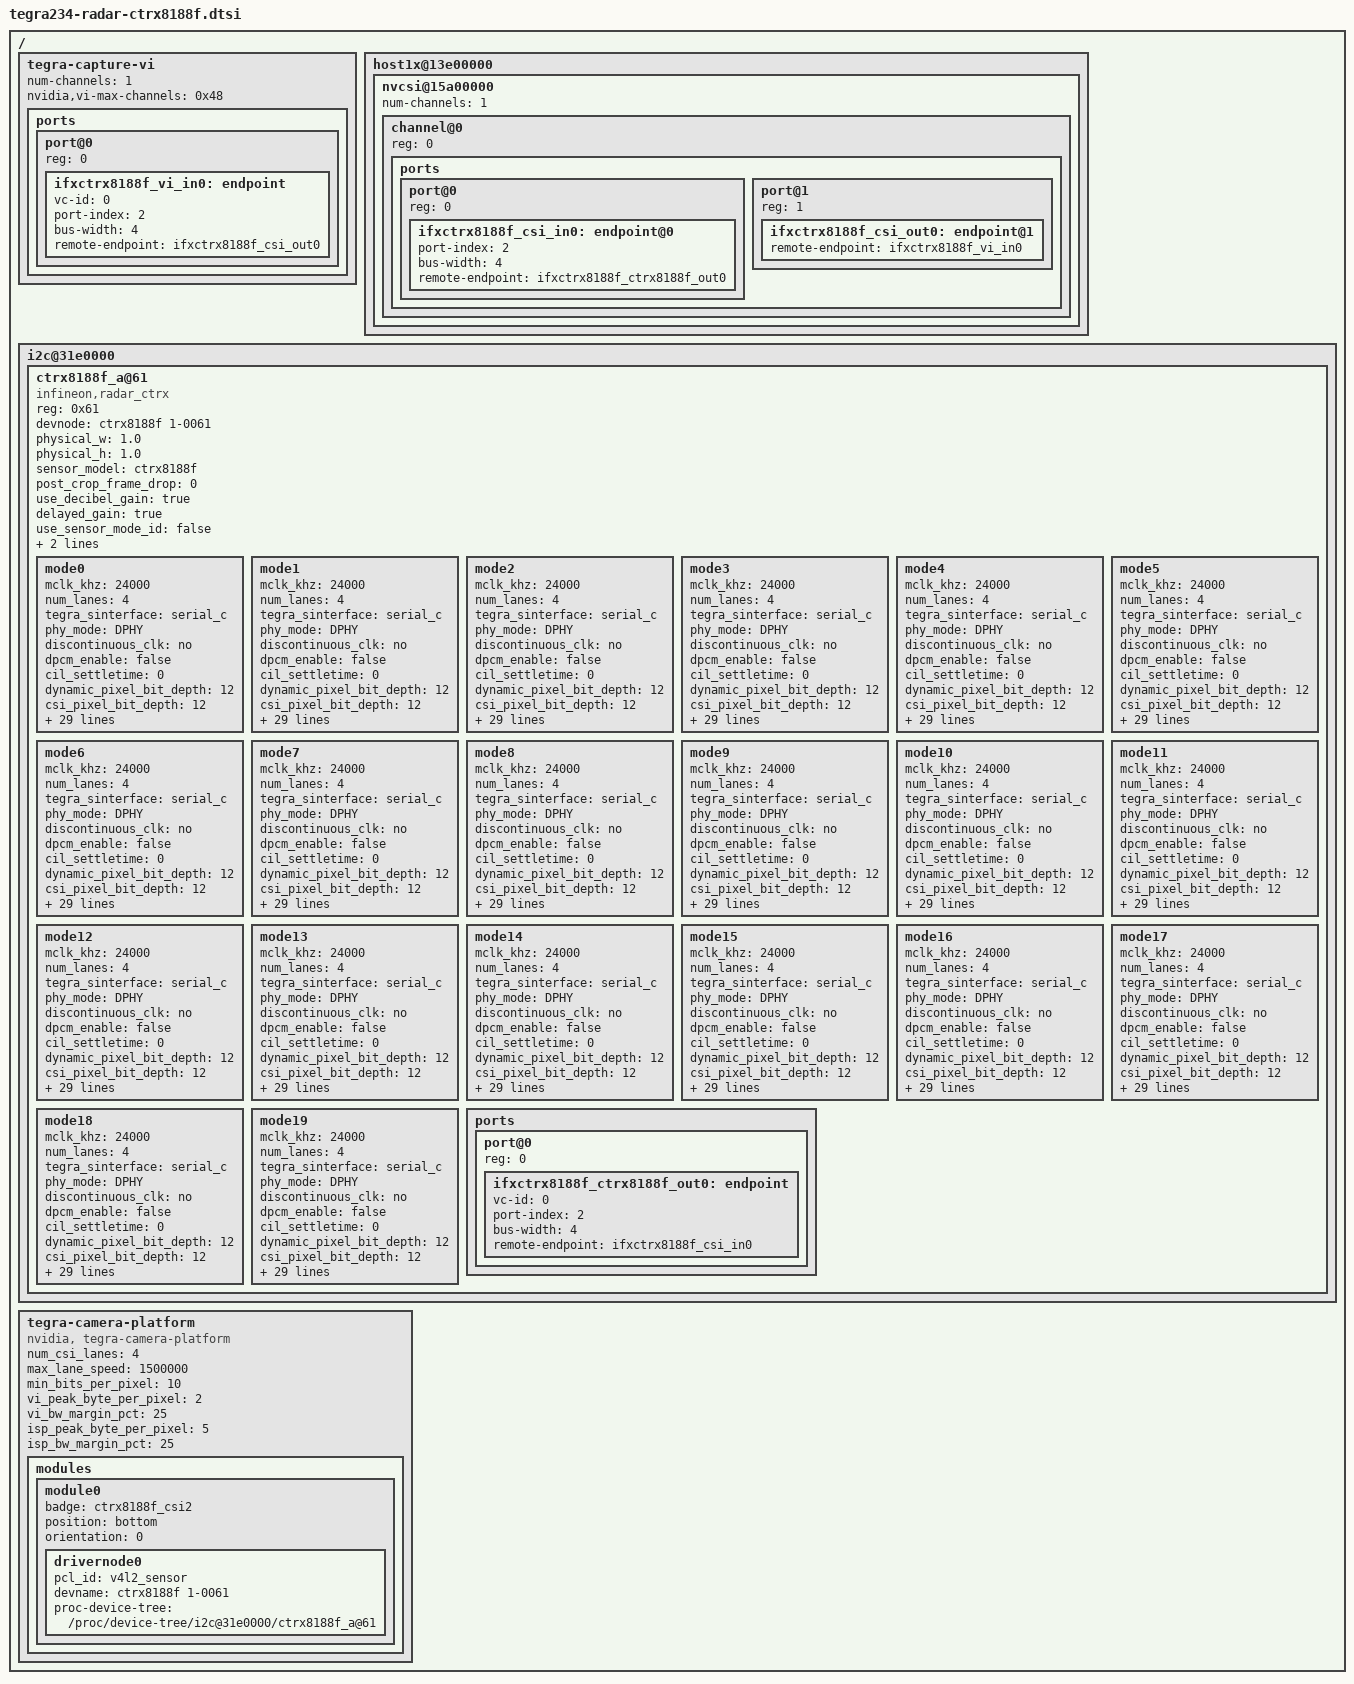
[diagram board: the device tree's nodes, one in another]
/*
 * Copyright (c) 2016-2021, NVIDIA CORPORATION.  All rights reserved.
 *
 * This program is free software; you can redistribute it and/or modify it
 * under the terms and conditions of the GNU General Public License,
 * version 2, as published by the Free Software Foundation.
 *
 * This program is distributed in the hope it will be useful, but WITHOUT
 * ANY WARRANTY; without even the implied warranty of MERCHANTABILITY or
 * FITNESS FOR A PARTICULAR PURPOSE.  See the GNU General Public License for
 * more details.
 *
 * You should have received a copy of the GNU General Public License
 * along with this program.  If not, see <http://www.gnu.org/licenses/>.
 */

/ {
	tegra-capture-vi {
		num-channels = <1>;
		nvidia,vi-max-channels = <0x48>;
		ports {
			#address-cells = <1>;
			#size-cells = <0>;
			port@0 {
				reg = <0>;
				status = "okay";
				ifxctrx8188f_vi_in0: endpoint {
					vc-id = <0>;
					port-index = <2>;
					bus-width = <4>;
					status = "okay";
					remote-endpoint = <&ifxctrx8188f_csi_out0>;
				};
			};
		};
	};

	host1x@13e00000 {
		nvcsi@15a00000 {
			num-channels = <1>;
			#address-cells = <1>;
			#size-cells = <0>;
			channel@0 {
				reg = <0>;
				status = "okay";
				ports {
					#address-cells = <1>;
					#size-cells = <0>;
					port@0 {
						reg = <0>;
						status = "okay";
						ifxctrx8188f_csi_in0: endpoint@0 {
							port-index = <2>;
							bus-width = <4>;
							status = "okay";
							remote-endpoint = <&ifxctrx8188f_ctrx8188f_out0>;
						};
					};
					port@1 {
						reg = <1>;
						status = "okay";
						ifxctrx8188f_csi_out0: endpoint@1 {
							status = "okay";
							remote-endpoint = <&ifxctrx8188f_vi_in0>;
						};
					};
				};
			};
		};
	};

	i2c@31e0000 {
    ctrx8188f_a@61 {
			compatible = "infineon,radar_ctrx";
			reg = <0x61>;
			devnode = "ctrx8188f 1-0061";
			physical_w = "1.0";
			physical_h = "1.0";
			sensor_model = "ctrx8188f";
			post_crop_frame_drop = "0";
			use_decibel_gain = "true";
			delayed_gain = "true";
			use_sensor_mode_id = "false";
			status = "okay";
			clocks = <0x02 0x24 0x02 0x24>;
			clock-names = "extperiph1", "pllp_grtba";
			mclk = "extperiph1";

			mode0 {
				mclk_khz = "24000";
				num_lanes = "4";
				tegra_sinterface = "serial_c";
				phy_mode = "DPHY";
				discontinuous_clk = "no";
				dpcm_enable = "false";
				cil_settletime = "0";
				dynamic_pixel_bit_depth = "12";
				csi_pixel_bit_depth = "12";
				mode_type = "bayer";
				pixel_phase = "rggb";
				vc_id = "0";
				active_w = "1024";
				active_h = "256";
				readout_orientation = "0";
				line_length = "1024";
				inherent_gain = "1";
				mclk_multiplier = "14.58";
				pix_clk_hz = "400000000";
				serdes_pix_clk_hz = "400000000";
				gain_factor = "10";
				min_gain_val = "10";
				max_gain_val = "110";
				step_gain_val = "1";
				default_gain = "10";
				min_hdr_ratio = "1";
				max_hdr_ratio = "1";
				framerate_factor = "1000000";
				min_framerate = "30000000";
				max_framerate = "30000000";
				step_framerate = "1";
				default_framerate = "30000000";
				exposure_factor = "1000000";
				min_exp_time = "30";
				max_exp_time = "33000";
				step_exp_time = "1";
				default_exp_time = "30000";
				embedded_metadata_height = "0";
			};

			mode1 {
			mclk_khz = "24000";
			num_lanes = "4";
			tegra_sinterface = "serial_c";
			phy_mode = "DPHY";
			discontinuous_clk = "no";
			dpcm_enable = "false";
			cil_settletime = "0";
			dynamic_pixel_bit_depth = "12";
			csi_pixel_bit_depth = "12";
			mode_type = "bayer";
			pixel_phase = "rggb";
			vc_id = "0";
			active_w = "2048";
			active_h = "256";
			readout_orientation = "0";
			line_length = "2048";
			inherent_gain = "1";
			mclk_multiplier = "14.58";
			pix_clk_hz = "400000000";
			serdes_pix_clk_hz = "400000000";
			gain_factor = "10";
			min_gain_val = "10";
			max_gain_val = "110";
			step_gain_val = "1";
			default_gain = "10";
			min_hdr_ratio = "1";
			max_hdr_ratio = "1";
			framerate_factor = "1000000";
			min_framerate = "30000000";
			max_framerate = "30000000";
			step_framerate = "1";
			default_framerate = "30000000";
			exposure_factor = "1000000";
			min_exp_time = "30";
			max_exp_time = "33000";
			step_exp_time = "1";
			default_exp_time = "30000";
			embedded_metadata_height = "0";
			};

			mode2 {
			mclk_khz = "24000";
			num_lanes = "4";
			tegra_sinterface = "serial_c";
			phy_mode = "DPHY";
			discontinuous_clk = "no";
			dpcm_enable = "false";
			cil_settletime = "0";
			dynamic_pixel_bit_depth = "12";
			csi_pixel_bit_depth = "12";
			mode_type = "bayer";
			pixel_phase = "rggb";
			vc_id = "0";
			active_w = "4096";
			active_h = "256";
			readout_orientation = "0";
			line_length = "4096";
			inherent_gain = "1";
			mclk_multiplier = "14.58";
			pix_clk_hz = "400000000";
			serdes_pix_clk_hz = "400000000";
			gain_factor = "10";
			min_gain_val = "10";
			max_gain_val = "110";
			step_gain_val = "1";
			default_gain = "10";
			min_hdr_ratio = "1";
			max_hdr_ratio = "1";
			framerate_factor = "1000000";
			min_framerate = "30000000";
			max_framerate = "30000000";
			step_framerate = "1";
			default_framerate = "30000000";
			exposure_factor = "1000000";
			min_exp_time = "30";
			max_exp_time = "33000";
			step_exp_time = "1";
			default_exp_time = "30000";
			embedded_metadata_height = "0";
			};

			mode3 {
			mclk_khz = "24000";
			num_lanes = "4";
			tegra_sinterface = "serial_c";
			phy_mode = "DPHY";
			discontinuous_clk = "no";
			dpcm_enable = "false";
			cil_settletime = "0";
			dynamic_pixel_bit_depth = "12";
			csi_pixel_bit_depth = "12";
			mode_type = "bayer";
			pixel_phase = "rggb";
			vc_id = "0";
			active_w = "8192";
			active_h = "256";
			readout_orientation = "0";
			line_length = "8192";
			inherent_gain = "1";
			mclk_multiplier = "14.58";
			pix_clk_hz = "400000000";
			serdes_pix_clk_hz = "400000000";
			gain_factor = "10";
			min_gain_val = "10";
			max_gain_val = "110";
			step_gain_val = "1";
			default_gain = "10";
			min_hdr_ratio = "1";
			max_hdr_ratio = "1";
			framerate_factor = "1000000";
			min_framerate = "30000000";
			max_framerate = "30000000";
			step_framerate = "1";
			default_framerate = "30000000";
			exposure_factor = "1000000";
			min_exp_time = "30";
			max_exp_time = "33000";
			step_exp_time = "1";
			default_exp_time = "30000";
			embedded_metadata_height = "0";
			};

			mode4 {
			mclk_khz = "24000";
			num_lanes = "4";
			tegra_sinterface = "serial_c";
			phy_mode = "DPHY";
			discontinuous_clk = "no";
			dpcm_enable = "false";
			cil_settletime = "0";
			dynamic_pixel_bit_depth = "12";
			csi_pixel_bit_depth = "12";
			mode_type = "bayer";
			pixel_phase = "rggb";
			vc_id = "0";
			active_w = "16384";
			active_h = "256";
			readout_orientation = "0";
			line_length = "16384";
			inherent_gain = "1";
			mclk_multiplier = "14.58";
			pix_clk_hz = "400000000";
			serdes_pix_clk_hz = "400000000";
			gain_factor = "10";
			min_gain_val = "10";
			max_gain_val = "110";
			step_gain_val = "1";
			default_gain = "10";
			min_hdr_ratio = "1";
			max_hdr_ratio = "1";
			framerate_factor = "1000000";
			min_framerate = "30000000";
			max_framerate = "30000000";
			step_framerate = "1";
			default_framerate = "30000000";
			exposure_factor = "1000000";
			min_exp_time = "30";
			max_exp_time = "33000";
			step_exp_time = "1";
			default_exp_time = "30000";
			embedded_metadata_height = "0";
			};

			mode5 {
			mclk_khz = "24000";
			num_lanes = "4";
			tegra_sinterface = "serial_c";
			phy_mode = "DPHY";
			discontinuous_clk = "no";
			dpcm_enable = "false";
			cil_settletime = "0";
			dynamic_pixel_bit_depth = "12";
			csi_pixel_bit_depth = "12";
			mode_type = "bayer";
			pixel_phase = "rggb";
			vc_id = "0";
			active_w = "1024";
			active_h = "512";
			readout_orientation = "0";
			line_length = "1024";
			inherent_gain = "1";
			mclk_multiplier = "14.58";
			pix_clk_hz = "400000000";
			serdes_pix_clk_hz = "400000000";
			gain_factor = "10";
			min_gain_val = "10";
			max_gain_val = "110";
			step_gain_val = "1";
			default_gain = "10";
			min_hdr_ratio = "1";
			max_hdr_ratio = "1";
			framerate_factor = "1000000";
			min_framerate = "30000000";
			max_framerate = "30000000";
			step_framerate = "1";
			default_framerate = "30000000";
			exposure_factor = "1000000";
			min_exp_time = "30";
			max_exp_time = "33000";
			step_exp_time = "1";
			default_exp_time = "30000";
			embedded_metadata_height = "0";
			};

			mode6 {
			mclk_khz = "24000";
			num_lanes = "4";
			tegra_sinterface = "serial_c";
			phy_mode = "DPHY";
			discontinuous_clk = "no";
			dpcm_enable = "false";
			cil_settletime = "0";
			dynamic_pixel_bit_depth = "12";
			csi_pixel_bit_depth = "12";
			mode_type = "bayer";
			pixel_phase = "rggb";
			vc_id = "0";
			active_w = "2048";
			active_h = "512";
			readout_orientation = "0";
			line_length = "2048";
			inherent_gain = "1";
			mclk_multiplier = "14.58";
			pix_clk_hz = "400000000";
			serdes_pix_clk_hz = "400000000";
			gain_factor = "10";
			min_gain_val = "10";
			max_gain_val = "110";
			step_gain_val = "1";
			default_gain = "10";
			min_hdr_ratio = "1";
			max_hdr_ratio = "1";
			framerate_factor = "1000000";
			min_framerate = "30000000";
			max_framerate = "30000000";
			step_framerate = "1";
			default_framerate = "30000000";
			exposure_factor = "1000000";
			min_exp_time = "30";
			max_exp_time = "33000";
			step_exp_time = "1";
			default_exp_time = "30000";
			embedded_metadata_height = "0";
			};

			mode7 {
			mclk_khz = "24000";
			num_lanes = "4";
			tegra_sinterface = "serial_c";
			phy_mode = "DPHY";
			discontinuous_clk = "no";
			dpcm_enable = "false";
			cil_settletime = "0";
			dynamic_pixel_bit_depth = "12";
			csi_pixel_bit_depth = "12";
			mode_type = "bayer";
			pixel_phase = "rggb";
			vc_id = "0";
			active_w = "4096";
			active_h = "512";
			readout_orientation = "0";
			line_length = "4096";
			inherent_gain = "1";
			mclk_multiplier = "14.58";
			pix_clk_hz = "400000000";
			serdes_pix_clk_hz = "400000000";
			gain_factor = "10";
			min_gain_val = "10";
			max_gain_val = "110";
			step_gain_val = "1";
			default_gain = "10";
			min_hdr_ratio = "1";
			max_hdr_ratio = "1";
			framerate_factor = "1000000";
			min_framerate = "30000000";
			max_framerate = "30000000";
			step_framerate = "1";
			default_framerate = "30000000";
			exposure_factor = "1000000";
			min_exp_time = "30";
			max_exp_time = "33000";
			step_exp_time = "1";
			default_exp_time = "30000";
			embedded_metadata_height = "0";
			};

			mode8 {
			mclk_khz = "24000";
			num_lanes = "4";
			tegra_sinterface = "serial_c";
			phy_mode = "DPHY";
			discontinuous_clk = "no";
			dpcm_enable = "false";
			cil_settletime = "0";
			dynamic_pixel_bit_depth = "12";
			csi_pixel_bit_depth = "12";
			mode_type = "bayer";
			pixel_phase = "rggb";
			vc_id = "0";
			active_w = "8192";
			active_h = "512";
			readout_orientation = "0";
			line_length = "8192";
			inherent_gain = "1";
			mclk_multiplier = "14.58";
			pix_clk_hz = "400000000";
			serdes_pix_clk_hz = "400000000";
			gain_factor = "10";
			min_gain_val = "10";
			max_gain_val = "110";
			step_gain_val = "1";
			default_gain = "10";
			min_hdr_ratio = "1";
			max_hdr_ratio = "1";
			framerate_factor = "1000000";
			min_framerate = "30000000";
			max_framerate = "30000000";
			step_framerate = "1";
			default_framerate = "30000000";
			exposure_factor = "1000000";
			min_exp_time = "30";
			max_exp_time = "33000";
			step_exp_time = "1";
			default_exp_time = "30000";
			embedded_metadata_height = "0";
			};

			mode9 {
			mclk_khz = "24000";
			num_lanes = "4";
			tegra_sinterface = "serial_c";
			phy_mode = "DPHY";
			discontinuous_clk = "no";
			dpcm_enable = "false";
			cil_settletime = "0";
			dynamic_pixel_bit_depth = "12";
			csi_pixel_bit_depth = "12";
			mode_type = "bayer";
			pixel_phase = "rggb";
			vc_id = "0";
			active_w = "16384";
			active_h = "512";
			readout_orientation = "0";
			line_length = "16384";
			inherent_gain = "1";
			mclk_multiplier = "14.58";
			pix_clk_hz = "400000000";
			serdes_pix_clk_hz = "400000000";
			gain_factor = "10";
			min_gain_val = "10";
			max_gain_val = "110";
			step_gain_val = "1";
			default_gain = "10";
			min_hdr_ratio = "1";
			max_hdr_ratio = "1";
			framerate_factor = "1000000";
			min_framerate = "30000000";
			max_framerate = "30000000";
			step_framerate = "1";
			default_framerate = "30000000";
			exposure_factor = "1000000";
			min_exp_time = "30";
			max_exp_time = "33000";
			step_exp_time = "1";
			default_exp_time = "30000";
			embedded_metadata_height = "0";
			};

			mode10 {
			mclk_khz = "24000";
			num_lanes = "4";
			tegra_sinterface = "serial_c";
			phy_mode = "DPHY";
			discontinuous_clk = "no";
			dpcm_enable = "false";
			cil_settletime = "0";
			dynamic_pixel_bit_depth = "12";
			csi_pixel_bit_depth = "12";
			mode_type = "bayer";
			pixel_phase = "rggb";
			vc_id = "0";
			active_w = "1024";
			active_h = "640";
			readout_orientation = "0";
			line_length = "1024";
			inherent_gain = "1";
			mclk_multiplier = "14.58";
			pix_clk_hz = "400000000";
			serdes_pix_clk_hz = "400000000";
			gain_factor = "10";
			min_gain_val = "10";
			max_gain_val = "110";
			step_gain_val = "1";
			default_gain = "10";
			min_hdr_ratio = "1";
			max_hdr_ratio = "1";
			framerate_factor = "1000000";
			min_framerate = "30000000";
			max_framerate = "30000000";
			step_framerate = "1";
			default_framerate = "30000000";
			exposure_factor = "1000000";
			min_exp_time = "30";
			max_exp_time = "33000";
			step_exp_time = "1";
			default_exp_time = "30000";
			embedded_metadata_height = "0";
			};

			mode11 {
			mclk_khz = "24000";
			num_lanes = "4";
			tegra_sinterface = "serial_c";
			phy_mode = "DPHY";
			discontinuous_clk = "no";
			dpcm_enable = "false";
			cil_settletime = "0";
			dynamic_pixel_bit_depth = "12";
			csi_pixel_bit_depth = "12";
			mode_type = "bayer";
			pixel_phase = "rggb";
			vc_id = "0";
			active_w = "2048";
			active_h = "640";
			readout_orientation = "0";
			line_length = "2048";
			inherent_gain = "1";
			mclk_multiplier = "14.58";
			pix_clk_hz = "400000000";
			serdes_pix_clk_hz = "400000000";
			gain_factor = "10";
			min_gain_val = "10";
			max_gain_val = "110";
			step_gain_val = "1";
			default_gain = "10";
			min_hdr_ratio = "1";
			max_hdr_ratio = "1";
			framerate_factor = "1000000";
			min_framerate = "30000000";
			max_framerate = "30000000";
			step_framerate = "1";
			default_framerate = "30000000";
			exposure_factor = "1000000";
			min_exp_time = "30";
			max_exp_time = "33000";
			step_exp_time = "1";
			default_exp_time = "30000";
			embedded_metadata_height = "0";
			};

			mode12 {
			mclk_khz = "24000";
			num_lanes = "4";
			tegra_sinterface = "serial_c";
			phy_mode = "DPHY";
			discontinuous_clk = "no";
			dpcm_enable = "false";
			cil_settletime = "0";
			dynamic_pixel_bit_depth = "12";
			csi_pixel_bit_depth = "12";
			mode_type = "bayer";
			pixel_phase = "rggb";
			vc_id = "0";
			active_w = "4096";
			active_h = "640";
			readout_orientation = "0";
			line_length = "4096";
			inherent_gain = "1";
			mclk_multiplier = "14.58";
			pix_clk_hz = "400000000";
			serdes_pix_clk_hz = "400000000";
			gain_factor = "10";
			min_gain_val = "10";
			max_gain_val = "110";
			step_gain_val = "1";
			default_gain = "10";
			min_hdr_ratio = "1";
			max_hdr_ratio = "1";
			framerate_factor = "1000000";
			min_framerate = "30000000";
			max_framerate = "30000000";
			step_framerate = "1";
			default_framerate = "30000000";
			exposure_factor = "1000000";
			min_exp_time = "30";
			max_exp_time = "33000";
			step_exp_time = "1";
			default_exp_time = "30000";
			embedded_metadata_height = "0";
			};

			mode13 {
			mclk_khz = "24000";
			num_lanes = "4";
			tegra_sinterface = "serial_c";
			phy_mode = "DPHY";
			discontinuous_clk = "no";
			dpcm_enable = "false";
			cil_settletime = "0";
			dynamic_pixel_bit_depth = "12";
			csi_pixel_bit_depth = "12";
			mode_type = "bayer";
			pixel_phase = "rggb";
			vc_id = "0";
			active_w = "8192";
			active_h = "640";
			readout_orientation = "0";
			line_length = "8192";
			inherent_gain = "1";
			mclk_multiplier = "14.58";
			pix_clk_hz = "400000000";
			serdes_pix_clk_hz = "400000000";
			gain_factor = "10";
			min_gain_val = "10";
			max_gain_val = "110";
			step_gain_val = "1";
			default_gain = "10";
			min_hdr_ratio = "1";
			max_hdr_ratio = "1";
			framerate_factor = "1000000";
			min_framerate = "30000000";
			max_framerate = "30000000";
			step_framerate = "1";
			default_framerate = "30000000";
			exposure_factor = "1000000";
			min_exp_time = "30";
			max_exp_time = "33000";
			step_exp_time = "1";
			default_exp_time = "30000";
			embedded_metadata_height = "0";
			};

			mode14 {
			mclk_khz = "24000";
			num_lanes = "4";
			tegra_sinterface = "serial_c";
			phy_mode = "DPHY";
			discontinuous_clk = "no";
			dpcm_enable = "false";
			cil_settletime = "0";
			dynamic_pixel_bit_depth = "12";
			csi_pixel_bit_depth = "12";
			mode_type = "bayer";
			pixel_phase = "rggb";
			vc_id = "0";
			active_w = "16384";
			active_h = "640";
			readout_orientation = "0";
			line_length = "16384";
			inherent_gain = "1";
			mclk_multiplier = "14.58";
			pix_clk_hz = "400000000";
			serdes_pix_clk_hz = "400000000";
			gain_factor = "10";
			min_gain_val = "10";
			max_gain_val = "110";
			step_gain_val = "1";
			default_gain = "10";
			min_hdr_ratio = "1";
			max_hdr_ratio = "1";
			framerate_factor = "1000000";
			min_framerate = "30000000";
			max_framerate = "30000000";
			step_framerate = "1";
			default_framerate = "30000000";
			exposure_factor = "1000000";
			min_exp_time = "30";
			max_exp_time = "33000";
			step_exp_time = "1";
			default_exp_time = "30000";
			embedded_metadata_height = "0";
			};

			mode15 {
			mclk_khz = "24000";
			num_lanes = "4";
			tegra_sinterface = "serial_c";
			phy_mode = "DPHY";
			discontinuous_clk = "no";
			dpcm_enable = "false";
			cil_settletime = "0";
			dynamic_pixel_bit_depth = "12";
			csi_pixel_bit_depth = "12";
			mode_type = "bayer";
			pixel_phase = "rggb";
			vc_id = "0";
			active_w = "1024";
			active_h = "1024";
			readout_orientation = "0";
			line_length = "1024";
			inherent_gain = "1";
			mclk_multiplier = "14.58";
			pix_clk_hz = "400000000";
			serdes_pix_clk_hz = "400000000";
			gain_factor = "10";
			min_gain_val = "10";
			max_gain_val = "110";
			step_gain_val = "1";
			default_gain = "10";
			min_hdr_ratio = "1";
			max_hdr_ratio = "1";
			framerate_factor = "1000000";
			min_framerate = "30000000";
			max_framerate = "30000000";
			step_framerate = "1";
			default_framerate = "30000000";
			exposure_factor = "1000000";
			min_exp_time = "30";
			max_exp_time = "33000";
			step_exp_time = "1";
			default_exp_time = "30000";
			embedded_metadata_height = "0";
			};

			mode16 {
			mclk_khz = "24000";
			num_lanes = "4";
			tegra_sinterface = "serial_c";
			phy_mode = "DPHY";
			discontinuous_clk = "no";
			dpcm_enable = "false";
			cil_settletime = "0";
			dynamic_pixel_bit_depth = "12";
			csi_pixel_bit_depth = "12";
			mode_type = "bayer";
			pixel_phase = "rggb";
			vc_id = "0";
			active_w = "2048";
			active_h = "1024";
			readout_orientation = "0";
			line_length = "2048";
			inherent_gain = "1";
			mclk_multiplier = "14.58";
			pix_clk_hz = "400000000";
			serdes_pix_clk_hz = "400000000";
			gain_factor = "10";
			min_gain_val = "10";
			max_gain_val = "110";
			step_gain_val = "1";
			default_gain = "10";
			min_hdr_ratio = "1";
			max_hdr_ratio = "1";
			framerate_factor = "1000000";
			min_framerate = "30000000";
			max_framerate = "30000000";
			step_framerate = "1";
			default_framerate = "30000000";
			exposure_factor = "1000000";
			min_exp_time = "30";
			max_exp_time = "33000";
			step_exp_time = "1";
			default_exp_time = "30000";
			embedded_metadata_height = "0";
			};

			mode17 {
			mclk_khz = "24000";
			num_lanes = "4";
			tegra_sinterface = "serial_c";
			phy_mode = "DPHY";
			discontinuous_clk = "no";
			dpcm_enable = "false";
			cil_settletime = "0";
			dynamic_pixel_bit_depth = "12";
			csi_pixel_bit_depth = "12";
			mode_type = "bayer";
			pixel_phase = "rggb";
			vc_id = "0";
			active_w = "4096";
			active_h = "1024";
			readout_orientation = "0";
			line_length = "4096";
			inherent_gain = "1";
			mclk_multiplier = "14.58";
			pix_clk_hz = "400000000";
			serdes_pix_clk_hz = "400000000";
			gain_factor = "10";
			min_gain_val = "10";
			max_gain_val = "110";
			step_gain_val = "1";
			default_gain = "10";
			min_hdr_ratio = "1";
			max_hdr_ratio = "1";
			framerate_factor = "1000000";
			min_framerate = "30000000";
			max_framerate = "30000000";
			step_framerate = "1";
			default_framerate = "30000000";
			exposure_factor = "1000000";
			min_exp_time = "30";
			max_exp_time = "33000";
			step_exp_time = "1";
			default_exp_time = "30000";
			embedded_metadata_height = "0";
			};

			mode18 {
			mclk_khz = "24000";
			num_lanes = "4";
			tegra_sinterface = "serial_c";
			phy_mode = "DPHY";
			discontinuous_clk = "no";
			dpcm_enable = "false";
			cil_settletime = "0";
			dynamic_pixel_bit_depth = "12";
			csi_pixel_bit_depth = "12";
			mode_type = "bayer";
			pixel_phase = "rggb";
			vc_id = "0";
			active_w = "8192";
			active_h = "1024";
			readout_orientation = "0";
			line_length = "8192";
			inherent_gain = "1";
			mclk_multiplier = "14.58";
			pix_clk_hz = "400000000";
			serdes_pix_clk_hz = "400000000";
			gain_factor = "10";
			min_gain_val = "10";
			max_gain_val = "110";
			step_gain_val = "1";
			default_gain = "10";
			min_hdr_ratio = "1";
			max_hdr_ratio = "1";
			framerate_factor = "1000000";
			min_framerate = "30000000";
			max_framerate = "30000000";
			step_framerate = "1";
			default_framerate = "30000000";
			exposure_factor = "1000000";
			min_exp_time = "30";
			max_exp_time = "33000";
			step_exp_time = "1";
			default_exp_time = "30000";
			embedded_metadata_height = "0";
			};

			mode19 {
			mclk_khz = "24000";
			num_lanes = "4";
			tegra_sinterface = "serial_c";
			phy_mode = "DPHY";
			discontinuous_clk = "no";
			dpcm_enable = "false";
			cil_settletime = "0";
			dynamic_pixel_bit_depth = "12";
			csi_pixel_bit_depth = "12";
			mode_type = "bayer";
			pixel_phase = "rggb";
			vc_id = "0";
			active_w = "16384";
			active_h = "1024";
			readout_orientation = "0";
			line_length = "16384";
			inherent_gain = "1";
			mclk_multiplier = "14.58";
			pix_clk_hz = "400000000";
			serdes_pix_clk_hz = "400000000";
			gain_factor = "10";
			min_gain_val = "10";
			max_gain_val = "110";
			step_gain_val = "1";
			default_gain = "10";
			min_hdr_ratio = "1";
			max_hdr_ratio = "1";
			framerate_factor = "1000000";
			min_framerate = "30000000";
			max_framerate = "30000000";
			step_framerate = "1";
			default_framerate = "30000000";
			exposure_factor = "1000000";
			min_exp_time = "30";
			max_exp_time = "33000";
			step_exp_time = "1";
			default_exp_time = "30000";
			embedded_metadata_height = "0";
			};

      ports {
        #address-cells = <1>;
        #size-cells = <0>;
        port@0 {
          reg = <0>;
          ifxctrx8188f_ctrx8188f_out0: endpoint {
						vc-id = <0>;
            port-index = <2>;
            bus-width = <4>;
            remote-endpoint = <&ifxctrx8188f_csi_in0>;
          };
        };
      };
    };	
	};
};

/ {

	tegra-camera-platform {
		compatible = "nvidia, tegra-camera-platform";

		num_csi_lanes = <4>;
		max_lane_speed = <1500000>;
		min_bits_per_pixel = <10>;
		vi_peak_byte_per_pixel = <2>;
		vi_bw_margin_pct = <25>;
		isp_peak_byte_per_pixel = <5>;
		isp_bw_margin_pct = <25>;

		modules {
			module0 {
				badge = "ctrx8188f_csi2";
				position = "bottom";
				orientation = "0";
				drivernode0 {
					/* Declare PCL support driver (classically known as guid)  */
					pcl_id = "v4l2_sensor";
					/* Driver v4l2 device name */
					devname = "ctrx8188f 1-0061";
					/* Declare the device-tree hierarchy to driver instance */
					proc-device-tree = "/proc/device-tree/i2c@31e0000/ctrx8188f_a@61";
				};
			};
		};
	};
};
